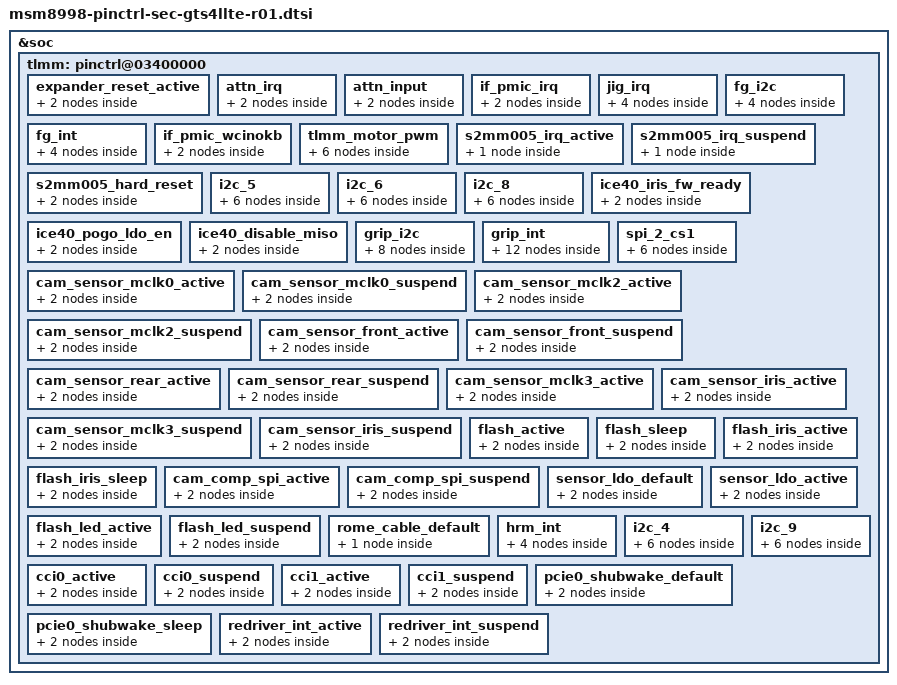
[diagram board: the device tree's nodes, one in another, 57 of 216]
/* Copyright (c) 2015-2016, The Linux Foundation. All rights reserved.
 *
 * This program is free software; you can redistribute it and/or modify
 * it under the terms of the GNU General Public License version 2 and
 * only version 2 as published by the Free Software Foundation.
 *
 * This program is distributed in the hope that it will be useful,
 * but WITHOUT ANY WARRANTY; without even the implied warranty of
 * MERCHANTABILITY or FITNESS FOR A PARTICULAR PURPOSE.  See the
 * GNU General Public License for more details.
 */

#include "msm8998-pinctrl-sec-gts4llte-audio.dtsi"

&soc {
	tlmm: pinctrl@03400000 {
		expander_reset_active: expander_reset_active {
			    mux {
				    pins = "gpio108";
				    function = "gpio";
			    };
			    config {
				    pins = "gpio108";
				    drive-strength = <2>;   /* 16 mA */
				    bias-disable;
				    output-high;
			    };
		    };

		attn_irq: attn_irq {
			mux {
				pins = "gpio121";
				function = "gpio";
			};
			config {
				pins = "gpio121";
				drive-strength = <2>;   /* 16 mA */
				bias-disable;
			};
		};
		attn_input: attn_input {
			mux {
				pins = "gpio121";
				function = "gpio";
			};
			config {
				pins = "gpio121";
				drive-strength = <2>;   /* 16 mA */
				bias-disable;
			};
		};

		if_pmic_irq: if_pmic_irq {
			mux {
				pins = "gpio37";
				function = "gpio";
			};
			config {
				pins = "gpio37";
				drive-strength = <2>;   /* 16 mA */
				input-enable;
				bias-disable;
			};
		};

		jig_irq {
			jig_irq_active: jig_irq_active {
				jig_irq_active {
					pins = "gpio91";
					drive-strength = <2>;
					bias-disable;
					input-enable;
				};
			};
			jig_irq_suspend: jig_irq_suspend {
				jig_irq_suspend {
					pins = "gpio91";
					drive-strength = <2>;
					bias-disable;
					input-enable;
				};
			};
		};

		fg_i2c {
			fg_i2c_active: fg_i2c_active {
				fg_i2c_active {
					pins = "gpio2", "gpio3";
					drive-strength = <2>;
					bias-disable;
				};
			};
			fg_i2c_suspend: fg_i2c_suspend {
				fg_i2c_suspend {
					pins = "gpio2", "gpio3";
					drive-strength = <2>;
					bias-disable;
				};
			};
		};

		fg_int {
			fg_int_active: fg_int_active {
				fg_int_active {
					pins = "gpio92";
					drive-strength = <2>;
					bias-disable;
				};
			};
			fg_int_suspend: fg_int_suspend {
				fg_int_suspend {
					pins = "gpio92";
					drive-strength = <2>;
					bias-disable;
				};
			};
		};

		if_pmic_wcinokb: if_pmic_wcinokb {
			mux {
				pins = "gpio108";
				function = "gpio";
			};
			config {
				pins = "gpio108";
				drive-strength = <2>;   /* 16 mA */
				input-enable;
				bias-disable;
			};
		};

		/* add pinctrl for motor  */
		tlmm_motor_pwm {
			motor_pwm_active: motor_pwm_active {
				mux {
					pins = "gpio57";
					function = "gcc_gp1_a";
				};
				config {
					pins = "gpio57";
					drive-strength = <2>;   /* 16 mA */
					bias-disable;
					output-high;
				};
			};
			motor_pwm_suspend: motor_pwm_suspend {
				mux {
					pins = "gpio57";
					function = "gpio";
				};
				config {
					pins = "gpio57";
					drive-strength = <2>;   /* 16 mA */
					bias-disable;
					output-low;
				};
			};
		};

		/* add pinctrl for ccic */
		s2mm005_irq_active: s2mm005_irq_active {
			i2c_7 {
				pins = "gpio50";
				drive-strength = <2>;
				function = "NA";
				bias-disable;
			};
		};

		s2mm005_irq_suspend: s2mm005_irq_suspend {
			i2c_7 {
				pins = "gpio50";
				drive-strength = <2>;
				function = "NA";
				bias-disable;
			};
		};

		s2mm005_hard_reset: s2mm005_hard_reset {
			mux {
				pins = "gpio55", "gpio56";
				function = "gpio";
			};

			config {
				pins = "gpio55", "gpio56";
				drive-strength = <6>;
				bias-pull-down;
				output-low;
			};
		};

		/delete-node/ i2c_5;
		i2c_5 {
			i2c_5_active: i2c_5_active {
				mux {
					pins = "gpio87", "gpio88";
					function = "blsp_i2c5";
				};

				config {
					pins = "gpio87", "gpio88";
					drive-strength = <2>;
					bias-disable;
				};
			};

			i2c_5_sleep: i2c_5_sleep {
				mux {
					pins = "gpio87", "gpio88";
					function = "blsp_i2c5";
				};

				config {
					pins = "gpio87", "gpio88";
					drive-strength = <2>;
					bias-disable;
				};
			};
		};

		/delete-node/ i2c_6;
		i2c_6 {
			i2c_6_active: i2c_6_active {
				mux {
					pins = "gpio43", "gpio44";
					function = "blsp_i2c6";
				};

				config {
					pins = "gpio43", "gpio44";
					drive-strength = <2>;
					bias-disable;
				};
			};

			i2c_6_sleep: i2c_6_sleep {
				mux {
					pins = "gpio43", "gpio44";
					function = "blsp_i2c6";
				};

				config {
					pins = "gpio43", "gpio44";
					drive-strength = <2>;
					bias-disable;
				};
			};
		};

		i2c_8 {
			i2c_8_active: i2c_8_active {
				mux {
					pins = "gpio6", "gpio7";
					function = "blsp_i2c8";
				};

				config {
					pins = "gpio6", "gpio7";
					drive-strength = <2>;
					bias-disable;
				};
			};

			i2c_8_sleep: i2c_8_sleep {
				mux {
					pins = "gpio6", "gpio7";
					function = "blsp_i2c8";
				};

				config {
					pins = "gpio6", "gpio7";
					drive-strength = <2>;
					/delete-property/ bias-pull-up;
					bias-disable;
				};
			};
		};

		ice40_iris_fw_ready: ice40_iris_fw_ready {
			    mux {
				    pins = "gpio8", "gpio81", "gpio84", "gpio85", "gpio89";
				    function = "gpio";
			    };
			    config {
				    pins = "gpio8", "gpio81", "gpio84", "gpio85", "gpio89";
				    drive-strength = <2>;   /* 16 mA */
				    bias-disable;
			    };
		};

		ice40_pogo_ldo_en: ice40_pogo_ldo_en {
			    mux {
				    pins = "gpio31";
				    function = "gpio";
			    };
			    config {
				    pins = "gpio31";
				    drive-strength = <2>;   /* 16 mA */
				    output-high;
				    bias-disable;
			    };
		};

		ice40_disable_miso: ice40_disable_miso {
			    mux {
				    pins = "gpio82";
				    function = "gpio";
			    };
			    config {
				    pins = "gpio82";
				    drive-strength = <2>;   /* 16 mA */
				    input-enable;
				    bias-pull-down;
			    };
		};

		grip_i2c {
			grip_i2c_active: grip_i2c_active {
				grip_i2c_active {
					pins = "gpio115", "gpio136";
					drive-strength = <2>;
					bias-disable;
				};
			};

			grip_i2c_suspend: grip_i2c_suspend {
				grip_i2c_suspend {
					pins = "gpio115", "gpio136";
					drive-strength = <2>;
					bias-disable;
				};
			};

			grip_wifi_i2c_active: grip_wifi_i2c_active {
				grip_wifi_i2c_active {
					pins = "gpio128", "gpio133";
					drive-strength = <2>;
					bias-disable;
				};
			};

			grip_wifi_i2c_suspend: grip_wifi_i2c_suspend {
				grip_wifi_i2c_suspend {
					pins = "gpio128", "gpio133";
					drive-strength = <2>;
					bias-disable;
				};
			};			
		};

		grip_int {
			grip_int_active: grip_int_active {
				grip_int_active {
					pins = "gpio127";
					drive-strength = <2>;
					bias-disable;
				};
			};

			grip_int_suspend: grip_int_suspend {
				grip_int_suspend {
					pins = "gpio127";
					drive-strength = <2>;
					bias-disable;
				};
			};

			grip_wifi_int_active: grip_wifi_int_active {
				grip_wifi_int_active {
					pins = "gpio79";
					drive-strength = <2>;
					bias-disable;
				};
			};

			grip_wifi_int_suspend: grip_wifi_int_suspend {
				grip_wifi_int_suspend {
					pins = "gpio79";
					drive-strength = <2>;
					bias-disable;
				};
			};

			grip_wifi_sub_int_active: grip_wifi_sub_int_active {
				grip_wifi_sub_int_active {
					pins = "gpio86";
					drive-strength = <2>;
					bias-disable;
				};
			};

			grip_wifi_sub_int_suspend: grip_wifi_sub_int_suspend {
				grip_wifi_sub_int_suspend {
					pins = "gpio86";
					drive-strength = <2>;
					bias-disable;
				};
			};			
		};

		spi_2_cs1 {
			/* CS1 */
			spi_2_cs1_active: spi_2_cs1_active {
				mux {
					pins = "gpio25";
					function = "blsp2_spi";
				};

				config {
					pins = "gpio25";
					drive-strength = <8>;
					bias-disable;
				};
			};

			spi_2_cs1_sleep: spi_2_cs1_sleep {
				mux {
					pins = "gpio25";
					function = "blsp2_spi";
				};

				config {
					pins = "gpio25";
					drive-strength = <8>;
					bias-pull-down;
				};
			};
		};

		cam_sensor_mclk0_active: cam_sensor_mclk0_active {
			/* MCLK0 */
			mux {
				/* CLK, DATA */
				pins = "gpio13";
				function = "cam_mclk";
			};

			config {
				pins = "gpio13";
				bias-disable; /* No PULL */
				drive-strength = <4>; /* 4 MA */
			};
		};

		cam_sensor_mclk0_suspend: cam_sensor_mclk0_suspend {
			/* MCLK0 */
			mux {
				/* CLK, DATA */
				pins = "gpio13";
				function = "cam_mclk";
			};

			config {
				pins = "gpio13";
				bias-pull-down; /* PULL DOWN */
				drive-strength = <4>; /* 4 MA */
			};
		};

		cam_sensor_mclk2_active: cam_sensor_mclk2_active {
			/* MCLK1 */
			mux {
				/* CLK, DATA */
				pins = "gpio15";
				function = "cam_mclk";
			};
			config {
				pins = "gpio15";
				bias-disable; /* No PULL */
				drive-strength = <4>; /* 4 MA */
			};
		};

		cam_sensor_mclk2_suspend: cam_sensor_mclk2_suspend{
			/* MCLK1 */
			mux {
				/* CLK, DATA */
				pins = "gpio15";
				function = "cam_mclk";
			};
			config {
				pins = "gpio15";
				bias-pull-down; /* PULL DOWN */
				drive-strength = <4>; /* 4 MA */
			};
		};

		cam_sensor_front_active: cam_sensor_front_active{
			/* RESET */
			mux {
				pins = "gpio28";
				function = "gpio";
			};

			config {
				pins = "gpio28";
				bias-disable; /* No PULL */
				drive-strength = <2>; /* 2 MA */
			};
		};

		cam_sensor_front_suspend: cam_sensor_front_suspend{
			/* RESET */
			mux {
				pins = "gpio28";
				function = "gpio";
			};

			config {
				pins = "gpio28";
				bias-pull-down;
				drive-strength = <2>; /* 2 MA */
			};
		};

		cam_sensor_rear_active: cam_sensor_rear_active {
			/* RESET */
			mux {
				pins = "gpio30";
				function = "gpio";
			};
			config {
				pins = "gpio30";
				bias-disable; /* No PULL */
				drive-strength = <2>; /* 2 MA */
			};
		};

		cam_sensor_rear_suspend: cam_sensor_rear_suspend{
			/* RESET */
			mux {
				pins = "gpio30";
				function = "gpio";
			};
			config {
				pins = "gpio30";
				bias-pull-down;
				drive-strength = <2>; /* 2 MA */
			};
		};

		cam_sensor_mclk3_active: cam_sensor_mclk3_active {
			/* MCLK3 */
			mux {
				/* CLK, DATA */
				pins = "gpio16";
				function = "cam_mclk";
			};
			config {
				pins = "gpio16";
				bias-disable; /* No PULL */
				drive-strength = <6>; /* 6 MA */
			};
		};

		cam_sensor_mclk3_suspend: cam_sensor_mclk3_suspend{
			/* MCLK3 */
			mux {
				/* CLK, DATA */
				pins = "gpio16";
				function = "cam_mclk";
			};
			config {
				pins = "gpio16";
				bias-pull-down; /* PULL DOWN */
				drive-strength = <6>; /* 6 MA */
			};
		};

		cam_sensor_iris_active: cam_sensor_iris_active {
                        /* RESET3 */
                        mux {
                                /* CLK, DATA */
                                pins = "gpio59", "gpio49";
                                function = "gpio";
                        };
                        config {
                                pins = "gpio59", "gpio49";
                                bias-disable; /* No PULL */
                                drive-strength = <4>; /* 4 MA */
                        };
                };

                cam_sensor_iris_suspend: cam_sensor_iris_suspend{
                        /* RESET3 */
                        mux {
                                /* CLK, DATA */
                                pins = "gpio59", "gpio49";
                                function = "gpio";
                        };
                        config {
                                pins = "gpio59", "gpio49";
                                bias-pull-down; /* PULL DOWN */
                                drive-strength = <4>; /* 4 MA */
                        };
                };
                flash_active: flash_active {
                                        /* TORCH*/
                        mux {
                                pins = "gpio22";
                                function = "gpio";
                        };

                        config {
                                pins = "gpio22";
                                bias-pull-down; /* PULL DOWN */
                                drive-strength = <2>; /* 2 MA */
                                output-low;
                        };
                };
                flash_sleep: flash_sleep {
                                        /* TORCH*/
                        mux {
                                pins = "gpio22";
                                function = "gpio";
                        };

                        config {
                                pins = "gpio22";
                                bias-pull-down; /* PULL DOWN */
                                drive-strength = <2>; /* 2 MA */
                                output-low;
                        };
                };

                flash_iris_active: flash_iris_active {
                                        /* TORCH*/
                        mux {
                                pins = "gpio21";
                                function = "gpio";
                        };

                        config {
                                pins = "gpio21";
                                bias-pull-down; /* PULL DOWN */
                                drive-strength = <2>; /* 2 MA */
                                output-low;
                        };
                };
                flash_iris_sleep: flash_iris_sleep {
                                        /* TORCH*/
                        mux {
                                pins = "gpio21";
                                function = "gpio";
                        };

                        config {
                                pins = "gpio21";
                                bias-pull-down; /* PULL DOWN */
                                drive-strength = <2>; /* 2 MA */
                                output-low;
                        };
                };


		cam_comp_spi_active: cam_comp_spi_active {
			/* COMP_INT */
			mux {
				pins = "gpio124";
				function = "gpio";
			};

			config {
				pins = "gpio124";
				bias-pull-up;
				drive-strength = <2>; /* 2 MA */
			};
		};

		cam_comp_spi_suspend: cam_comp_spi_suspend {
			/* COMP_INT */
			mux {
				pins = "gpio124";
				function = "gpio";
			};

			config {
				pins = "gpio124";
				bias-pull-down;
				drive-strength = <2>; /* 2 MA */
			};
		};

		sensor_ldo_default: sensor_ldo_default {
			mux {
				pins = "gpio26";
				function = "gpio";
			};

			config {
				pins = "gpio26";
				bias-disable; /* No PULL */
				drive-strength = <2>; /* 2 MA */
				output-low;
			};
		};

		sensor_ldo_active: sensor_ldo_active {
			mux {
				pins = "gpio26";
				function = "gpio";
			};

			config {
				pins = "gpio26";
				bias-disable; /* No PULL */
				drive-strength = <2>; /* 2 MA */
				output-high;
			};
		};

		flash_led_active: flash_led_active {
			mux {
				pins = "gpio21","gpio22";
				function = "gpio";
			};

			config {
				pins = "gpio21","gpio22";
				bias-disable; /* No PULL */
				drive-strength = <2>; /* 2 MA */
			};
		};

		flash_led_suspend: flash_led_suspend {
			mux {
				pins = "gpio21","gpio22";
				function = "gpio";
			};

			config {
				pins = "gpio21","gpio22";
				bias-disable; /* No PULL */
				drive-strength = <2>; /* 2 MA */
				output-low;
			};
		};
		rome_cable_default: rome_cable_default {
			config {
				pins = "gpio105","gpio106";
				bias-disable;
			};
		};
		hrm_int {
			hrm_int_active: hrm_int_active {
				hrm_int {
					pins = "gpio122";
					drive-strength = <2>;
					bias-disable;
				};
			};
			hrm_int_suspend: hrm_int_suspend {
				hrm_int {
					pins = "gpio122";
					drive-strength = <2>;
					bias-disable;
				};
			};
		};

		i2c_4 {
			i2c_4_active: i2c_4_active {
				mux {
					pins = "gpio10", "gpio11";
					function = "blsp_i2c4";
				};

				config {
					pins = "gpio10", "gpio11";
					drive-strength = <2>;
					bias-disable;
				};
			};

			i2c_4_sleep: i2c_4_sleep {
				mux {
					pins = "gpio10", "gpio11";
					function = "blsp_i2c4";
				};

				config {
					pins = "gpio10", "gpio11";
					drive-strength = <2>;
					bias-pull-down;
				};
			};
		};

		cam_sensor_iris_active: cam_sensor_iris_active {
		/* RESET */
			mux {
				pins = "gpio41", "gpio42";
				function = "gpio";
			};

			config {
				pins = "gpio41", "gpio42";
				bias-disable; /* No PULL */
				drive-strength = <2>; /* 2 MA */
			};
		};

		cam_sensor_iris_suspend: cam_sensor_iris_suspend {
		/* RESET */
			mux {
				pins = "gpio41", "gpio42";
				function = "gpio";
			};

			config {
				pins = "gpio41", "gpio42";
				bias-pull-down;
				output-low;
				drive-strength = <2>; /* 2 MA */
			};
		};

		i2c_9 {
			i2c_9_active: i2c_9_active {
				mux {
					pins = "gpio51", "gpio52";
					function = "blsp_i2c9";
				};

				config {
					pins = "gpio51", "gpio52";
					drive-strength = <2>;
					bias-disable;
				};
			};

			i2c_9_sleep: i2c_9_sleep {
				mux {
					pins = "gpio51", "gpio52";
					function = "blsp_i2c9";
				};

				config {
					pins = "gpio51", "gpio52";
					drive-strength = <2>;
					/delete-property/ bias-pull-up;
					bias-disable;
				};
			};
		};

		cci0_active: cci0_active {
			mux {
				/* CLK, DATA */
				pins = "gpio17","gpio18"; // Only 2
				function = "cci_i2c";
			};

			config {
				pins = "gpio17","gpio18";
				bias-pull-up; /* PULL UP*/
				drive-strength = <2>; /* 2 MA */
			};
		};

		cci0_suspend: cci0_suspend {
			mux {
				/* CLK, DATA */
				pins = "gpio17","gpio18";
				function = "gpio";
			};

			config {
				pins = "gpio17","gpio18";
				bias-pull-down; /* PULL DOWN */
				drive-strength = <2>; /* 2 MA */
				input-disable;
			};
		};

		cci1_active: cci1_active {
			mux {
				/* CLK, DATA */
				pins = "gpio19","gpio20";
				function = "cci_i2c";
			};

			config {
				pins = "gpio19","gpio20";
				bias-pull-up; /* PULL UP*/
				drive-strength = <2>; /* 2 MA */
			};
		};

		cci1_suspend: cci1_suspend {
			mux {
				/* CLK, DATA */
				pins = "gpio19","gpio20";
				function = "gpio";
			};

			config {
				pins = "gpio19","gpio20";
				bias-pull-down; /* PULL DOWN */
				drive-strength = <2>; /* 2 MA */
				input-disable;
			};
		};

		pcie0_shubwake_default: pcie0_shubwake_default {
			mux {
				pins = "gpio117";
				function = "gpio";
			};

			config {
				pins = "gpio117";
				drive-strength = <2>;
				bias-pull-up;
			};
		};

		pcie0_shubwake_sleep: pcie0_shubwake_sleep {
			mux {
				pins = "gpio117";
				function = "gpio";
			};

			config {
				pins = "gpio117";
				drive-strength = <2>;
				bias-pull-up;
			};
		};

		redriver_int_active: redriver_int_active {
			mux {
				pins = "gpio9";
				function = "gpio";
			};

			config {
				pins = "gpio9";
				drive-strength = <2>;
				bias-disable;
			};
		};

		redriver_int_suspend: redriver_int_suspend {
			mux {
				pins = "gpio9";
				function = "gpio";
			};

			config {
				pins = "gpio9";
				drive-strength = <2>;
				bias-disable;
			};
		};
	};
};
